# PIC32CM5112SG00100 register map
Vendor: Microchip Technology; Series: PIC32CMSG00; File version: 0
CPU: CM23 r0p0, little endian, MPU, no FPU, 2 interrupt priority bits, 141 interrupts, 13 SAU regions
Registers are 32-bit, read-write, reset 0x0 unless marked. A register's access mark holds for its fields unless they carry their own. Offsets are from the block's base; [hi:lo] are bit positions; {n}, {i} and the like mark numbered series; 'fields as' and 'values as' point back to an identical list.

## FCW — Polaris Flash Write Controller
Base 0x44004000
0x00 CTRLA — Control A REGISTER
  [2] PRIV — Privileged Access Only
    0=DISABLE (Macro register accessible in privileged and unprivileged accesses.); 1=ENABLE (Macro registers only accessible in privileged accesses)
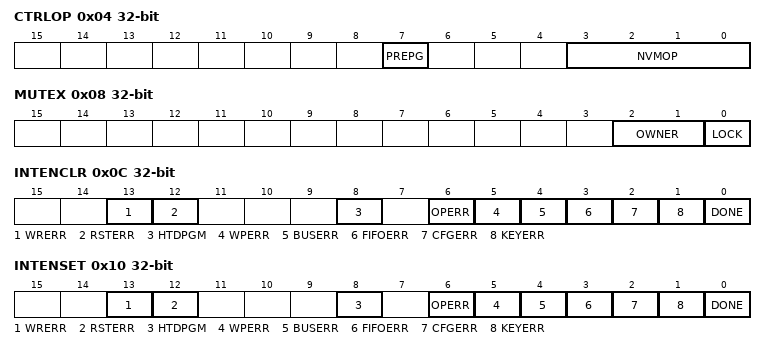
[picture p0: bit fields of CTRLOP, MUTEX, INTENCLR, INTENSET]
0x04 CTRLOP — Control Operation REGISTER
  [7] PREPG — NVM Pre-Program Configuration Bit
    0=DISABLE (Program Operations exclude Pre-Program step); 1=ENABLE (Program Operations include Pre-Program step)
  [3:0] NVMOP — NVM Operation
    0=NOP (No Operation); 1=SINGLEWRITE (Single (Word) Program Operation: Programs word selected by ADDR); 2=QUADWRITE (Quad (Word) Program Operation: Programs flash word selected by ADDR); 3=ROWWRITE (Row Write Operation: Programs row selected by ADDR); 4=PAGEERASE (Page Erase Operation: Erases page selected by ADDR); 5=LPFMERASE (Lower PFM Erase Operation: (RSVD NVMOP for Single Panel Devices)); 6=UPFMERASE (Upper PFM Erase Operation: (RSVD NVMOP for Single Panel Devices)); 7=PFMERASE (PFM Erase Operation: Upper & Lower PFM Erase); 14=CE (Chip Erase Operation: Erases PFM+SRF, BFM, CFM (except for CalOTP, Test, VSS pages if HSM is Present, UserOTP, & ROMCFG).)
0x08 MUTEX
  [2:1] OWNER — Flash Write Controller (FCW) Owner ID
    0=NONE (No Owner - always 0 if LOCK=0); 1=SYSTEM (The System owns the FCW)
  [0] LOCK — Flash Write Controller (FCW) Lock by Owner
    0=UNLOCK (FCW is not locked); 1=LOCK (FCW is locked by owner)
0x0C INTENCLR write-1-clears — Interrupt Enable Clear REGISTER
  [all] fields
    0=Interrupt Disabled; 1=Interrupt Enabled
  [13] WRERR — Write Error Interrupt Enable
  [12] RSTERR — Reset or Brown Out Detect Error Interrupt Enable
  [8] HTDPGM — High Temperature Detect Error Interrupt Enable
  [6] OPERR — NVMOP Error Interrupt Enable
  [5] WPERR — Write Protection Error Interrupt Enable
  [4] BUSERR — AHB Bus Error during Row Write Interrupt Enable
  [3] FIFOERR — FIFO Underrun during Row Write Interrupt Enable
  [2] CFGERR — Configuration Error Interrupt Enable
  [1] KEYERR — Key Error Interrupt Enable
  [0] DONE — NVM Operation Done Interrupt Enable
0x10 INTENSET write-1-sets — Interrupt Enable Set REGISTER
  [all] fields
    0=Interrupt Disabled; 1=Interrupt Enabled
  [13] WRERR — Write Error Interrupt Enable
  [12] RSTERR — Reset or Brown Out Detect Error Interrupt Enable
  [8] HTDPGM — High Temperature Detect Error Interrupt Enable
  [6] OPERR — NVMOP Error Interrupt Enable
  [5] WPERR — Write Protection Error Interrupt Enable
  [4] BUSERR — AHB Bus Error during Row Write Interrupt Enable
  [3] FIFOERR — FIFO Underrun during Row Write Interrupt Set Enable
  [2] CFGERR — Configuration Error Interrupt Set Enable
  [1] KEYERR — Key Error Interrupt Set Enable
  [0] DONE — NVM Operation Done Interrupt Set Enable
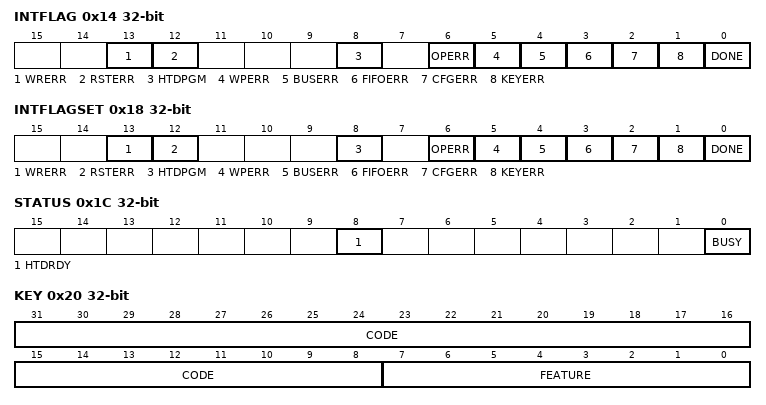
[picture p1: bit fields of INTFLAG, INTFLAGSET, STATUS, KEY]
0x14 INTFLAG write-1-clears — Interrupt Flag REGISTER
  [13] WRERR — Write Error Flag Bit
    0=The Write/Erase sequence completed normally; 1=The Write/Erase sequence did not complete successfully
  [12] RSTERR — Reset or Brown Out Detect Error Flag Bit
    0=No Reset and Voltage level OK during write/erase; 1=A reset or Low Voltage Detected (possible data corruption, verify data)
  [8] HTDPGM — High Temperature Detect Error Flag Bit
    0=High Temp NOT Detected; 1=High Temp Detected (possible data corruption, verify operation)
  [6] OPERR — NVMOP Error Flag Bit
    0=No NVMOP Error; 1=Selected Operation is Disabled Error
  [5] WPERR — Write Protection Error Flag Bit
    0=No Write Protection Error; 1=Write Protection Error
  [4] BUSERR — AHB Bus Error during Row Write Flag Bit
    0=No Bus Error; 1=Bus Error
  [3] FIFOERR — FIFO Underrun during Row Write Flag Bit
    0=No FIFO Error; 1=FIFO Error
  [2] CFGERR — Configuration Error Flag Bit
    0=No CFG Error; 1=CFC Error
  [1] KEYERR — Key Error Flag Bit
    0=No Key Error; 1=Key Error
  [0] DONE — NVM Operation Done Flag Bit
    0=NVMOP Not Done; 1=NVMOP Done
0x18 INTFLAGSET write-1-clears — Interrupt Flag Set REGISTER
  [all] fields
    0=No effect; 1=Set Interrupt Pending
  [13] WRERR — Write Error Set Flag Bit
  [12] RSTERR — Reset or Brown Out Detect Error Set Flag Bit
  [8] HTDPGM — High Temperature Detect Error Set Flag Bit
  [6] OPERR — NVMOP Error Set Flag Bit
  [5] WPERR — Write Protection Error Set Flag Bit
  [4] BUSERR — AHB Bus Error during Row Write Set Flag Bit
  [3] FIFOERR — FIFO Underrun during Row Write Set Flag Bit
  [2] CFGERR — Configuration Error Set Flag Bit
  [1] KEYERR — Key Error Set Flag Bit
  [0] DONE — NVM Operation Done Set Flag Bit
0x1C STATUS ro
  [8] HTDRDY — High Temp Detect Ready Status
    0=NOTREADY (HTD Not Ready); 1=READY (HTD Ready)
  [0] BUSY — NVM Busy Status
    0=IDLE (NVM Not Busy); 1=BUSY (NVM Busy - All SFR bits are not writable)
0x20 KEY — Feature Unlock Key REGISTER
  [31:8] CODE — Unlock Code
  [7:0] FEATURE — Feature Select
    0=LOCKALL (No selection, invalid selection, or invalid Key - Locks all SFR protected by KEY register); 1=WRKEY (WRKEY Value: Unlock SFR bits associated with Write/Erase); 2=SWAPKEY (SWAPKEY Value: Unlock SFR bits associated with Panel Swapping); 4=CFGKEY (CFGKEY Value: Unlock SFR bits associated with general Flash configuration)
0x24 ADDR — Flash Destination Address REGISTER
  [31:0] ADDR — Flash Address used by NVMOP
0x28 SRCADDR — System Source Address REGISTER
  [31:0] SRCADDR — Source Data (Word) Address
{0x2C+4i} DATA[{i}] (i=0..3) — Flash Write Data n REGISTER
  [31:0] DATA — Flash Write Data
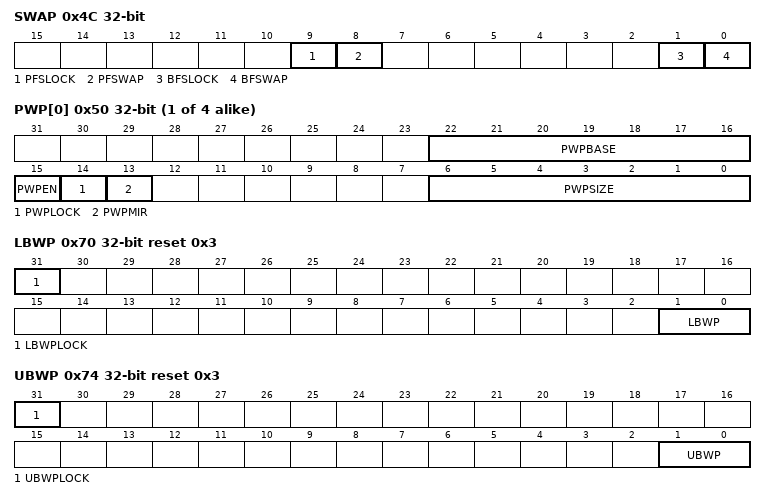
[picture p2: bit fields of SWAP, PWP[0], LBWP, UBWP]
0x4C SWAP — NVM Panel Swap REGISTER
  [9] PFSLOCK — PFM Swap Lock Bit
    0=UNLOCKED (PFSLOCK and PFSWAP can be written); 1=LOCKED (PFSLOCK and PFSWAP cannot be written)
  [8] PFSWAP — PFM Swap Status/Control Bit
    0=UNSWAP (Upper and Lower PFM Regions are NOT Swapped); 1=SWAP (Upper and Lower PFM Regions are Swapped)
  [1] BFSLOCK — BFM Swap Lock Bit
    0=UNLOCKED (BFSLOCK and BFSWAP can be written); 1=LOCKED (BFSLOCK and BFSWAP cannot be written)
  [0] BFSWAP — BFM Swap Status/Control Bit
    0=UNSWAP (Upper and Lower BFM Regions are NOT Swapped); 1=SWAP (Upper and Lower BFM Regions are Swapped)
{0x50+4i} PWP[{i}] (i=0..3) — PFM Write Protect Region n REGISTER
  [22:16] PWPBASE — PWP Base Address - 4KB Page Aligned
  [15] PWPEN — PWP Enable Bit
    0=DISABLE (PWP is Not Enabled for the defined region); 1=ENABLE (PWP is Enabled for the defined region)
  [14] PWPLOCK — PWP Lock Bit
    0=UNLOCKED (This register is Not Locked and can be modified); 1=LOCKED (This register is Locked and cannot be modified)
  [13] PWPMIR — Mirror PWP bit
    0=UNMIRROR (PWP settings are NOT Mirrored); 1=MIRROR (PWP settings are Mirrored)
  [6:0] PWPSIZE — PWP Size in 4KB pages
0x70 LBWP reset 0x3 — Lower BFM Write Protect REGISTER
  [31] LBWPLOCK — LBWP Lock Bit
    0=UNLOCKED (This register is NOT Locked and can be modified); 1=LOCKED (This register is Locked and cannot be modified)
  [1:0] LBWP — Lower Boot Pages Write Protect Bits
    0=DISABLE (Erase and Write Protection for this Lower Boot Page is Disabled); 1=ENABLE (Erase and Write Protection for this Lower Boot Page is Enabled)
0x74 UBWP reset 0x3 — Upper BFM Write Protect REGISTER
  [31] UBWPLOCK — UBWP Lock Bit
    values as LBWP.LBWPLOCK
  [1:0] UBWP — Upper Boot Pages Write Protect Bits
    0=DISABLE (Erase and Write Protection for this Upper Boot Page is Disabled); 1=ENABLE (Erase and Write Protection for this Upper Boot Page is Enabled)
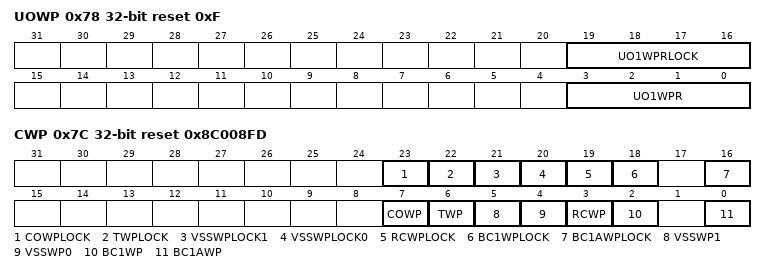
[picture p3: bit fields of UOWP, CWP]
0x78 UOWP reset 0xF — User OTP Write protection REGISTER
  [19:16] UO1WPRLOCK — User OTP Page 1 WP Row Lock Bit
    0=UNLOCKED (UO1WPR[n] & UO1WPRLOCK[n] bits are NOT Locked and can be modified); 1=LOCKED (UO1WPR[n] & UO1WPRLOCK[n] bits are Locked and cannot be modified)
  [3:0] UO1WPR — User OTP Page 1 Write Protect Row Bit
    0=DISABLE (Write Protection for User OTP Page 1 Row 'n' is Disabled); 1=ENABLE (Write Protection for User OTP Page 1 Row 'n' is Enabled)
0x7C CWP reset 0x8C008FD — CFM Page Write Protect REGISTER
  [23] COWPLOCK — Panel 1 Lock Write Protection CalOTP
    0=UNLOCKED (The Lock & Write Protect bits for this Page are NOT Locked and can be modified); 1=LOCKED (The Lock & Write Protect bits for this Page are Locked and cannot be modified)
  [22] TWPLOCK — Panel 1 Lock Write Protection Test
    values as COWPLOCK
  [21] VSSWPLOCK1 — Panel 1 Lock Write Protection VSSn
    values as COWPLOCK
  [20] VSSWPLOCK0 — Panel 1 Lock Write Protection VSSn
    values as COWPLOCK
  [19] RCWPLOCK — Panel 1 Lock Write Protection ROMCfg
    values as COWPLOCK
  [18] BC1WPLOCK — Panel 1 Lock Write Protection BootCfg1
    values as COWPLOCK
  [16] BC1AWPLOCK — Panel 1 Lock Write Protection BootCfg1A
    values as COWPLOCK
  [7] COWP — Panel 1 Write Protect CalOTP
    0=DISABLE (Erase and Write Protection for this Page is Disabled); 1=ENABLE (Erase and Write Protection for this Page is Enabled)
  [6] TWP — Panel 1 Write Protect Test
    0=DISABLE (Erase and Write Protection for this Page is Disabled); 1=ENABLE (Erase and Write Protection for this Page is Enable)
  [5] VSSWP1 — Panel 1 Write Protect VSSn
    values as COWP
  [4] VSSWP0 — Panel 1 Write Protect VSSn
    values as COWP
  [3] RCWP — Panel 1 Write Protect ROMCfg
    values as COWP
  [2] BC1WP — Panel 1 Write Protect BootCfg1
    values as COWP
  [0] BC1AWP — Panel 1 Write Protect BootCfg1A
    values as COWP
